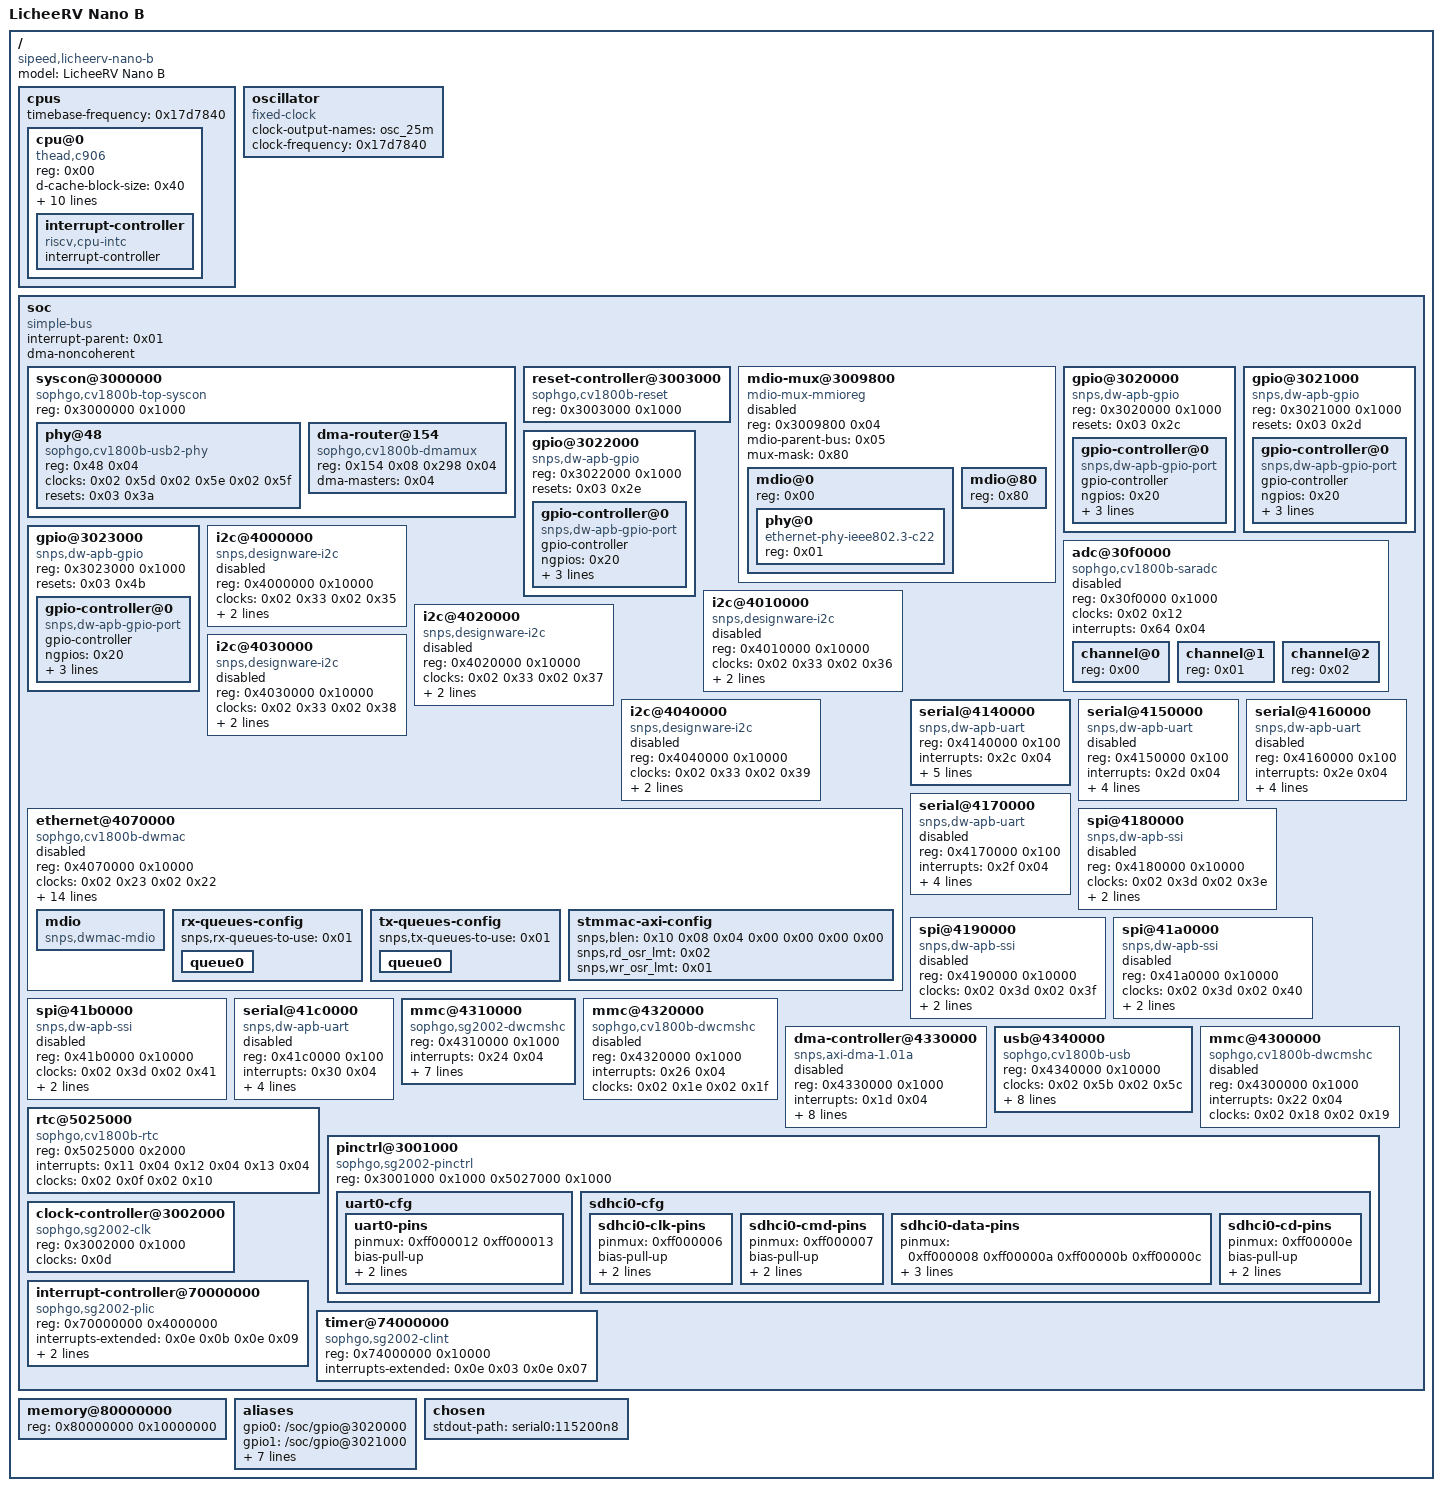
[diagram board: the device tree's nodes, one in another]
/dts-v1/;

/ {
	#address-cells = <0x01>;
	#size-cells = <0x01>;
	compatible = "sipeed,licheerv-nano-b\0sipeed,licheerv-nano\0sophgo,sg2002";
	model = "LicheeRV Nano B";

	cpus {
		#address-cells = <0x01>;
		#size-cells = <0x00>;
		timebase-frequency = <0x17d7840>;

		cpu@0 {
			compatible = "thead,c906\0riscv";
			device_type = "cpu";
			reg = <0x00>;
			d-cache-block-size = <0x40>;
			d-cache-sets = <0x200>;
			d-cache-size = <0x10000>;
			i-cache-block-size = <0x40>;
			i-cache-sets = <0x80>;
			i-cache-size = <0x8000>;
			mmu-type = "riscv,sv39";
			riscv,isa = "rv64imafdc";
			riscv,isa-base = "rv64i";
			riscv,isa-extensions = "i\0m\0a\0f\0d\0c\0zicntr\0zicsr\0zifencei\0zihpm";

			interrupt-controller {
				compatible = "riscv,cpu-intc";
				interrupt-controller;
				#interrupt-cells = <0x01>;
				phandle = <0x0e>;
			};
		};
	};

	oscillator {
		compatible = "fixed-clock";
		clock-output-names = "osc_25m";
		#clock-cells = <0x00>;
		clock-frequency = <0x17d7840>;
		phandle = <0x0d>;
	};

	soc {
		compatible = "simple-bus";
		#address-cells = <0x01>;
		#size-cells = <0x01>;
		ranges;
		interrupt-parent = <0x01>;
		dma-noncoherent;

		syscon@3000000 {
			compatible = "sophgo,cv1800b-top-syscon\0syscon\0simple-mfd";
			reg = <0x3000000 0x1000>;
			#address-cells = <0x01>;
			#size-cells = <0x01>;

			phy@48 {
				compatible = "sophgo,cv1800b-usb2-phy";
				reg = <0x48 0x04>;
				#phy-cells = <0x00>;
				clocks = <0x02 0x5d 0x02 0x5e 0x02 0x5f>;
				clock-names = "app\0stb\0lpm";
				resets = <0x03 0x3a>;
				phandle = <0x0c>;
			};

			dma-router@154 {
				compatible = "sophgo,cv1800b-dmamux";
				reg = <0x154 0x08 0x298 0x04>;
				#dma-cells = <0x02>;
				dma-masters = <0x04>;
			};
		};

		reset-controller@3003000 {
			compatible = "sophgo,cv1800b-reset";
			reg = <0x3003000 0x1000>;
			#reset-cells = <0x01>;
			phandle = <0x03>;
		};

		mdio-mux@3009800 {
			compatible = "mdio-mux-mmioreg\0mdio-mux";
			reg = <0x3009800 0x04>;
			#address-cells = <0x01>;
			#size-cells = <0x00>;
			mdio-parent-bus = <0x05>;
			mux-mask = <0x80>;
			status = "disabled";

			mdio@0 {
				#address-cells = <0x01>;
				#size-cells = <0x00>;
				reg = <0x00>;

				phy@0 {
					compatible = "ethernet-phy-ieee802.3-c22";
					reg = <0x01>;
					phandle = <0x06>;
				};
			};

			mdio@80 {
				#address-cells = <0x01>;
				#size-cells = <0x00>;
				reg = <0x80>;
			};
		};

		gpio@3020000 {
			compatible = "snps,dw-apb-gpio";
			reg = <0x3020000 0x1000>;
			#address-cells = <0x01>;
			#size-cells = <0x00>;
			resets = <0x03 0x2c>;

			gpio-controller@0 {
				compatible = "snps,dw-apb-gpio-port";
				gpio-controller;
				#gpio-cells = <0x02>;
				ngpios = <0x20>;
				reg = <0x00>;
				interrupt-controller;
				#interrupt-cells = <0x02>;
				interrupts = <0x3c 0x04>;
			};
		};

		gpio@3021000 {
			compatible = "snps,dw-apb-gpio";
			reg = <0x3021000 0x1000>;
			#address-cells = <0x01>;
			#size-cells = <0x00>;
			resets = <0x03 0x2d>;

			gpio-controller@0 {
				compatible = "snps,dw-apb-gpio-port";
				gpio-controller;
				#gpio-cells = <0x02>;
				ngpios = <0x20>;
				reg = <0x00>;
				interrupt-controller;
				#interrupt-cells = <0x02>;
				interrupts = <0x3d 0x04>;
			};
		};

		gpio@3022000 {
			compatible = "snps,dw-apb-gpio";
			reg = <0x3022000 0x1000>;
			#address-cells = <0x01>;
			#size-cells = <0x00>;
			resets = <0x03 0x2e>;

			gpio-controller@0 {
				compatible = "snps,dw-apb-gpio-port";
				gpio-controller;
				#gpio-cells = <0x02>;
				ngpios = <0x20>;
				reg = <0x00>;
				interrupt-controller;
				#interrupt-cells = <0x02>;
				interrupts = <0x3e 0x04>;
			};
		};

		gpio@3023000 {
			compatible = "snps,dw-apb-gpio";
			reg = <0x3023000 0x1000>;
			#address-cells = <0x01>;
			#size-cells = <0x00>;
			resets = <0x03 0x4b>;

			gpio-controller@0 {
				compatible = "snps,dw-apb-gpio-port";
				gpio-controller;
				#gpio-cells = <0x02>;
				ngpios = <0x20>;
				reg = <0x00>;
				interrupt-controller;
				#interrupt-cells = <0x02>;
				interrupts = <0x3f 0x04>;
			};
		};

		adc@30f0000 {
			compatible = "sophgo,cv1800b-saradc";
			reg = <0x30f0000 0x1000>;
			clocks = <0x02 0x12>;
			interrupts = <0x64 0x04>;
			#address-cells = <0x01>;
			#size-cells = <0x00>;
			status = "disabled";

			channel@0 {
				reg = <0x00>;
			};

			channel@1 {
				reg = <0x01>;
			};

			channel@2 {
				reg = <0x02>;
			};
		};

		i2c@4000000 {
			compatible = "snps,designware-i2c";
			reg = <0x4000000 0x10000>;
			#address-cells = <0x01>;
			#size-cells = <0x00>;
			clocks = <0x02 0x33 0x02 0x35>;
			clock-names = "ref\0pclk";
			interrupts = <0x31 0x04>;
			resets = <0x03 0x1b>;
			status = "disabled";
		};

		i2c@4010000 {
			compatible = "snps,designware-i2c";
			reg = <0x4010000 0x10000>;
			#address-cells = <0x01>;
			#size-cells = <0x00>;
			clocks = <0x02 0x33 0x02 0x36>;
			clock-names = "ref\0pclk";
			interrupts = <0x32 0x04>;
			resets = <0x03 0x1c>;
			status = "disabled";
		};

		i2c@4020000 {
			compatible = "snps,designware-i2c";
			reg = <0x4020000 0x10000>;
			#address-cells = <0x01>;
			#size-cells = <0x00>;
			clocks = <0x02 0x33 0x02 0x37>;
			clock-names = "ref\0pclk";
			interrupts = <0x33 0x04>;
			resets = <0x03 0x1d>;
			status = "disabled";
		};

		i2c@4030000 {
			compatible = "snps,designware-i2c";
			reg = <0x4030000 0x10000>;
			#address-cells = <0x01>;
			#size-cells = <0x00>;
			clocks = <0x02 0x33 0x02 0x38>;
			clock-names = "ref\0pclk";
			interrupts = <0x34 0x04>;
			resets = <0x03 0x1e>;
			status = "disabled";
		};

		i2c@4040000 {
			compatible = "snps,designware-i2c";
			reg = <0x4040000 0x10000>;
			#address-cells = <0x01>;
			#size-cells = <0x00>;
			clocks = <0x02 0x33 0x02 0x39>;
			clock-names = "ref\0pclk";
			interrupts = <0x35 0x04>;
			resets = <0x03 0x1f>;
			status = "disabled";
		};

		ethernet@4070000 {
			compatible = "sophgo,cv1800b-dwmac\0snps,dwmac-3.70a";
			reg = <0x4070000 0x10000>;
			clocks = <0x02 0x23 0x02 0x22>;
			clock-names = "stmmaceth\0ptp_ref";
			interrupts = <0x1f 0x04>;
			interrupt-names = "macirq";
			phy-handle = <0x06>;
			phy-mode = "internal";
			resets = <0x03 0x0c>;
			reset-names = "stmmaceth";
			rx-fifo-depth = <0x2000>;
			tx-fifo-depth = <0x2000>;
			snps,multicast-filter-bins = <0x00>;
			snps,perfect-filter-entries = <0x01>;
			snps,aal;
			snps,txpbl = <0x08>;
			snps,rxpbl = <0x08>;
			snps,mtl-rx-config = <0x07>;
			snps,mtl-tx-config = <0x08>;
			snps,axi-config = <0x09>;
			status = "disabled";

			mdio {
				compatible = "snps,dwmac-mdio";
				#address-cells = <0x01>;
				#size-cells = <0x00>;
				phandle = <0x05>;
			};

			rx-queues-config {
				snps,rx-queues-to-use = <0x01>;
				phandle = <0x07>;

				queue0 {
				};
			};

			tx-queues-config {
				snps,tx-queues-to-use = <0x01>;
				phandle = <0x08>;

				queue0 {
				};
			};

			stmmac-axi-config {
				snps,blen = <0x10 0x08 0x04 0x00 0x00 0x00 0x00>;
				snps,rd_osr_lmt = <0x02>;
				snps,wr_osr_lmt = <0x01>;
				phandle = <0x09>;
			};
		};

		serial@4140000 {
			compatible = "snps,dw-apb-uart";
			reg = <0x4140000 0x100>;
			interrupts = <0x2c 0x04>;
			clocks = <0x02 0x4d 0x02 0x4e>;
			clock-names = "baudclk\0apb_pclk";
			reg-shift = <0x02>;
			reg-io-width = <0x04>;
			resets = <0x03 0x17>;
			status = "okay";
			pinctrl-0 = <0x0a>;
			pinctrl-names = "default";
		};

		serial@4150000 {
			compatible = "snps,dw-apb-uart";
			reg = <0x4150000 0x100>;
			interrupts = <0x2d 0x04>;
			clocks = <0x02 0x4f 0x02 0x50>;
			clock-names = "baudclk\0apb_pclk";
			reg-shift = <0x02>;
			reg-io-width = <0x04>;
			resets = <0x03 0x18>;
			status = "disabled";
		};

		serial@4160000 {
			compatible = "snps,dw-apb-uart";
			reg = <0x4160000 0x100>;
			interrupts = <0x2e 0x04>;
			clocks = <0x02 0x51 0x02 0x52>;
			clock-names = "baudclk\0apb_pclk";
			reg-shift = <0x02>;
			reg-io-width = <0x04>;
			resets = <0x03 0x19>;
			status = "disabled";
		};

		serial@4170000 {
			compatible = "snps,dw-apb-uart";
			reg = <0x4170000 0x100>;
			interrupts = <0x2f 0x04>;
			clocks = <0x02 0x53 0x02 0x54>;
			clock-names = "baudclk\0apb_pclk";
			reg-shift = <0x02>;
			reg-io-width = <0x04>;
			resets = <0x03 0x1a>;
			status = "disabled";
		};

		spi@4180000 {
			compatible = "snps,dw-apb-ssi";
			reg = <0x4180000 0x10000>;
			#address-cells = <0x01>;
			#size-cells = <0x00>;
			clocks = <0x02 0x3d 0x02 0x3e>;
			clock-names = "ssi_clk\0pclk";
			interrupts = <0x36 0x04>;
			resets = <0x03 0x28>;
			status = "disabled";
		};

		spi@4190000 {
			compatible = "snps,dw-apb-ssi";
			reg = <0x4190000 0x10000>;
			#address-cells = <0x01>;
			#size-cells = <0x00>;
			clocks = <0x02 0x3d 0x02 0x3f>;
			clock-names = "ssi_clk\0pclk";
			interrupts = <0x37 0x04>;
			resets = <0x03 0x29>;
			status = "disabled";
		};

		spi@41a0000 {
			compatible = "snps,dw-apb-ssi";
			reg = <0x41a0000 0x10000>;
			#address-cells = <0x01>;
			#size-cells = <0x00>;
			clocks = <0x02 0x3d 0x02 0x40>;
			clock-names = "ssi_clk\0pclk";
			interrupts = <0x38 0x04>;
			resets = <0x03 0x2a>;
			status = "disabled";
		};

		spi@41b0000 {
			compatible = "snps,dw-apb-ssi";
			reg = <0x41b0000 0x10000>;
			#address-cells = <0x01>;
			#size-cells = <0x00>;
			clocks = <0x02 0x3d 0x02 0x41>;
			clock-names = "ssi_clk\0pclk";
			interrupts = <0x39 0x04>;
			resets = <0x03 0x2b>;
			status = "disabled";
		};

		serial@41c0000 {
			compatible = "snps,dw-apb-uart";
			reg = <0x41c0000 0x100>;
			interrupts = <0x30 0x04>;
			clocks = <0x02 0x55 0x02 0x56>;
			clock-names = "baudclk\0apb_pclk";
			reg-shift = <0x02>;
			reg-io-width = <0x04>;
			resets = <0x03 0x4a>;
			status = "disabled";
		};

		mmc@4310000 {
			compatible = "sophgo,sg2002-dwcmshc";
			reg = <0x4310000 0x1000>;
			interrupts = <0x24 0x04>;
			clocks = <0x02 0x1b 0x02 0x1c>;
			clock-names = "core\0bus";
			status = "okay";
			pinctrl-0 = <0x0b>;
			pinctrl-names = "default";
			bus-width = <0x04>;
			no-1-8-v;
			no-mmc;
			no-sdio;
			disable-wp;
		};

		mmc@4320000 {
			compatible = "sophgo,cv1800b-dwcmshc";
			reg = <0x4320000 0x1000>;
			interrupts = <0x26 0x04>;
			clocks = <0x02 0x1e 0x02 0x1f>;
			clock-names = "core\0bus";
			status = "disabled";
		};

		dma-controller@4330000 {
			compatible = "snps,axi-dma-1.01a";
			reg = <0x4330000 0x1000>;
			interrupts = <0x1d 0x04>;
			clocks = <0x02 0x2e 0x02 0x2e>;
			clock-names = "core-clk\0cfgr-clk";
			#dma-cells = <0x01>;
			dma-channels = <0x08>;
			snps,block-size = <0x400 0x400 0x400 0x400 0x400 0x400 0x400 0x400>;
			snps,priority = <0x00 0x01 0x02 0x03 0x04 0x05 0x06 0x07>;
			snps,dma-masters = <0x02>;
			snps,data-width = <0x02>;
			status = "disabled";
			phandle = <0x04>;
		};

		usb@4340000 {
			compatible = "sophgo,cv1800b-usb";
			reg = <0x4340000 0x10000>;
			clocks = <0x02 0x5b 0x02 0x5c>;
			clock-names = "otg\0utmi";
			g-np-tx-fifo-size = <0x20>;
			g-rx-fifo-size = <0x600>;
			g-tx-fifo-size = <0x80 0x80 0x40 0x40 0x40 0x40 0x20 0x20>;
			interrupts = <0x1e 0x04>;
			phys = <0x0c>;
			phy-names = "usb2-phy";
			resets = <0x03 0x0b>;
			reset-names = "dwc2";
			status = "okay";
			dr_mode = "host";
		};

		rtc@5025000 {
			compatible = "sophgo,cv1800b-rtc\0syscon";
			reg = <0x5025000 0x2000>;
			interrupts = <0x11 0x04 0x12 0x04 0x13 0x04>;
			interrupt-names = "alarm\0longpress\0vbat";
			clocks = <0x02 0x0f 0x02 0x10>;
			clock-names = "rtc\0mcu";
		};

		mmc@4300000 {
			compatible = "sophgo,cv1800b-dwcmshc";
			reg = <0x4300000 0x1000>;
			interrupts = <0x22 0x04>;
			clocks = <0x02 0x18 0x02 0x19>;
			clock-names = "core\0bus";
			status = "disabled";
		};

		pinctrl@3001000 {
			compatible = "sophgo,sg2002-pinctrl";
			reg = <0x3001000 0x1000 0x5027000 0x1000>;
			reg-names = "sys\0rtc";

			uart0-cfg {
				phandle = <0x0a>;

				uart0-pins {
					pinmux = <0xff000012 0xff000013>;
					bias-pull-up;
					drive-strength-microamp = <0x2a30>;
					power-source = <0xce4>;
				};
			};

			sdhci0-cfg {
				phandle = <0x0b>;

				sdhci0-clk-pins {
					pinmux = <0xff000006>;
					bias-pull-up;
					drive-strength-microamp = <0x3ee4>;
					power-source = <0xce4>;
				};

				sdhci0-cmd-pins {
					pinmux = <0xff000007>;
					bias-pull-up;
					drive-strength-microamp = <0x2a30>;
					power-source = <0xce4>;
				};

				sdhci0-data-pins {
					pinmux = <0xff000008 0xff00000a 0xff00000b 0xff00000c>;
					bias-pull-up;
					drive-strength-microamp = <0x2a30>;
					power-source = <0xce4>;
				};

				sdhci0-cd-pins {
					pinmux = <0xff00000e>;
					bias-pull-up;
					drive-strength-microamp = <0x2a30>;
					power-source = <0xce4>;
				};
			};
		};

		clock-controller@3002000 {
			compatible = "sophgo,sg2002-clk\0sophgo,sg2000-clk";
			reg = <0x3002000 0x1000>;
			clocks = <0x0d>;
			#clock-cells = <0x01>;
			phandle = <0x02>;
		};

		interrupt-controller@70000000 {
			compatible = "sophgo,sg2002-plic\0thead,c900-plic";
			reg = <0x70000000 0x4000000>;
			interrupts-extended = <0x0e 0x0b 0x0e 0x09>;
			interrupt-controller;
			#address-cells = <0x00>;
			#interrupt-cells = <0x02>;
			riscv,ndev = <0x65>;
			phandle = <0x01>;
		};

		timer@74000000 {
			compatible = "sophgo,sg2002-clint\0thead,c900-clint";
			reg = <0x74000000 0x10000>;
			interrupts-extended = <0x0e 0x03 0x0e 0x07>;
		};
	};

	memory@80000000 {
		device_type = "memory";
		reg = <0x80000000 0x10000000>;
	};

	aliases {
		gpio0 = "/soc/gpio@3020000";
		gpio1 = "/soc/gpio@3021000";
		gpio2 = "/soc/gpio@3022000";
		gpio3 = "/soc/gpio@3023000";
		serial0 = "/soc/serial@4140000";
		serial1 = "/soc/serial@4150000";
		serial2 = "/soc/serial@4160000";
		serial3 = "/soc/serial@4170000";
		serial4 = "/soc/serial@41c0000";
	};

	chosen {
		stdout-path = "serial0:115200n8";
	};
};
